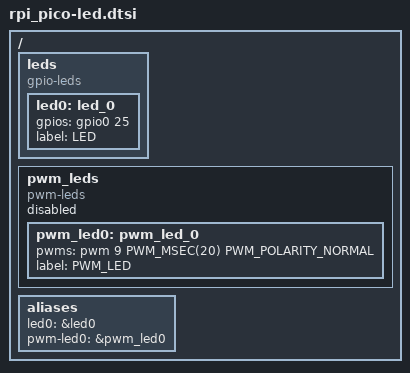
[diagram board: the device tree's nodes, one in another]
/*
 * Copyright (c) 2021 Yonatan Schachter
 *
 * SPDX-License-Identifier: Apache-2.0
 */

/* Pico and Pico 2 boards (but not Pico W) have a common LED placement. */
/ {
	leds {
		compatible = "gpio-leds";

		led0: led_0 {
			gpios = <&gpio0 25 GPIO_ACTIVE_HIGH>;
			label = "LED";
		};
	};

	pwm_leds {
		compatible = "pwm-leds";
		status = "disabled";

		pwm_led0: pwm_led_0 {
			pwms = <&pwm 9 PWM_MSEC(20) PWM_POLARITY_NORMAL>;
			label = "PWM_LED";
		};
	};

	aliases {
		led0 = &led0;
		pwm-led0 = &pwm_led0;
	};
};
